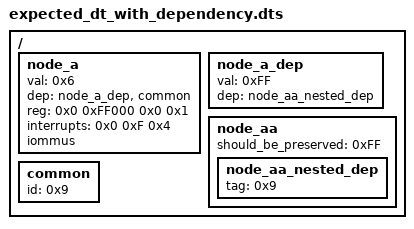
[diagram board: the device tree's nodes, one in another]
/dts-v1/;

/include/ "platform_preprocessed.dts"

// Note: This uses manually written __symbols__ so we don't

/ {
    node_a: node_a {
        phandle = <0x2E>;
        val = <0x6>;
        dep = <&node_a_dep &common>;
        reg = <0x0 0xFF000 0x0 0x1>;
        interrupts = <0x0 0xF 0x4>;
        iommus;
    };

    node_a_dep: node_a_dep {
        phandle = <0x31>;
        val = <0xFF>;
        dep = <&node_aa_nested_dep>;
    };

    node_aa {
        should_be_preserved = <0xFF>;

        node_aa_nested_dep: node_aa_nested_dep {
            phandle = <0x33>;
            tag = <0x9>;
        };
    };

    common: common {
        phandle = <0x32>;
        id = <0x9>;
    };

    /delete-node/ pviommu0;
    /delete-node/ pviommu1;
    /delete-node/ pviommu2;
    /delete-node/ pviommu3;
    /delete-node/ pviommu4;
    /delete-node/ pviommu5;
    /delete-node/ pviommu6;
    /delete-node/ pviommu7;
    /delete-node/ pviommu8;
    /delete-node/ pviommu9;
};
